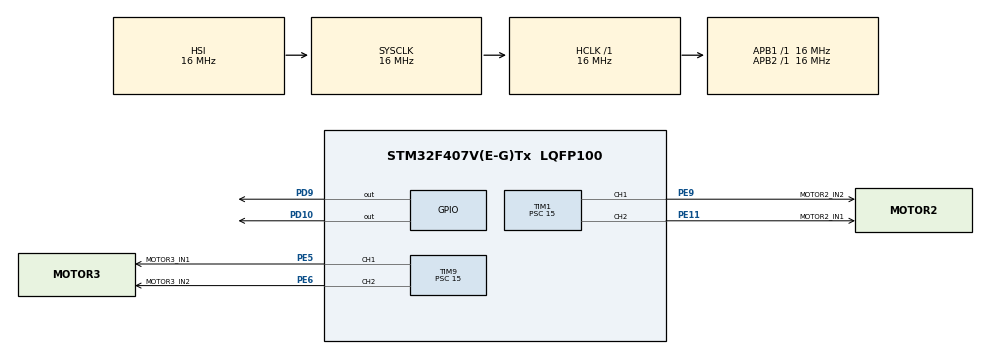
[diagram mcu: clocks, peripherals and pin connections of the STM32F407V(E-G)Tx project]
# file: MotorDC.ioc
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Mcu.Family=STM32F4
Mcu.Name=STM32F407V(E-G)Tx
Mcu.Package=LQFP100
NVIC.PriorityGroup=NVIC_PRIORITYGROUP_4
PD10.Signal=GPIO_Output
PD9.Signal=GPIO_Output
PE11.GPIO_Label=MOTOR2_IN1
PE11.Signal=S_TIM1_CH2
PE5.GPIO_Label=MOTOR3_IN1
PE5.Signal=S_TIM9_CH1
PE6.GPIO_Label=MOTOR3_IN2
PE6.Signal=S_TIM9_CH2
PE9.GPIO_Label=MOTOR2_IN2
PE9.Signal=S_TIM1_CH1
ProjectManager.HeapSize=0x200
ProjectManager.StackSize=0x400
ProjectManager.TargetToolchain=STM32CubeIDE
RCC.AHBFreq_Value=16000000
RCC.APB1Freq_Value=16000000
RCC.APB2Freq_Value=16000000
RCC.CortexFreq_Value=16000000
RCC.HSE_VALUE=25000000
RCC.HSI_VALUE=16000000
RCC.LSE_VALUE=32768
RCC.SYSCLKFreq_VALUE=16000000
RCC.VCOOutputFreq_Value=192000000
SH.S_TIM1_CH1.0=TIM1_CH1,PWM Generation1 CH1
SH.S_TIM1_CH2.0=TIM1_CH2,PWM Generation2 CH2
SH.S_TIM9_CH1.0=TIM9_CH1,PWM Generation1 CH1
SH.S_TIM9_CH2.0=TIM9_CH2,PWM Generation2 CH2
TIM1.Channel-PWM\ Generation1\ CH1=TIM_CHANNEL_1
TIM1.Channel-PWM\ Generation2\ CH2=TIM_CHANNEL_2
TIM1.Period=999
TIM1.Prescaler=15
TIM9.Channel-PWM\ Generation1\ CH1=TIM_CHANNEL_1
TIM9.Channel-PWM\ Generation2\ CH2=TIM_CHANNEL_2
TIM9.Period=999
TIM9.Prescaler=15
board=custom

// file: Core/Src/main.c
/* USER CODE BEGIN Header */
/**
  ******************************************************************************
  * @file           : main.c
  * @brief          : Main program body
  ******************************************************************************
  * @attention
  *
  * Copyright (c) 2026 STMicroelectronics.
  * All rights reserved.
  *
  * This software is licensed under terms that can be found in the LICENSE file
  * in the root directory of this software component.
  * If no LICENSE file comes with this software, it is provided AS-IS.
  *
  ******************************************************************************
  */
/* USER CODE END Header */
#include "main.h"

TIM_HandleTypeDef htim1;
TIM_HandleTypeDef htim9;

void SystemClock_Config(void);
static void MX_GPIO_Init(void);
static void MX_TIM1_Init(void);
static void MX_TIM9_Init(void);

int main(void)
{

  /* MCU Configuration--------------------------------------------------------*/

  /* Reset of all peripherals, Initializes the Flash interface and the Systick. */
  HAL_Init();

  /* Configure the system clock */
  SystemClock_Config();

  /* Initialize all configured peripherals */
  MX_GPIO_Init();
  MX_TIM1_Init();
  MX_TIM9_Init();
  /* USER CODE BEGIN 2 */
  // Encendemos los dos canales PWM del Motor 2

    // Encendemos los canales PWM del Motor 2 (M2)
  HAL_TIM_PWM_Start(&htim1, TIM_CHANNEL_1);
  HAL_TIM_PWM_Start(&htim1, TIM_CHANNEL_2);

    // Encendemos los canales PWM del Motor 3 (M3)
  HAL_TIM_PWM_Start(&htim9, TIM_CHANNEL_1); // PE5
  HAL_TIM_PWM_Start(&htim9, TIM_CHANNEL_2); // PE6

  /* USER CODE END 2 */

  /* Infinite loop */
  /* USER CODE BEGIN WHILE */
  /* USER CODE BEGIN WHILE */
    while (1)
    {
    /* USER CODE END WHILE */

    /* USER CODE BEGIN 3 */

    	/* USER CODE BEGIN 3 */

    	    // ==========================================
    	    // ESTADO 1: AVANZAR AMBOS AL 100% (Potencia Máxima)
    	    // ==========================================
    	    HAL_GPIO_WritePin(GPIOD, GPIO_PIN_9, GPIO_PIN_SET);   // Prende LED 1
    	    HAL_GPIO_WritePin(GPIOD, GPIO_PIN_10, GPIO_PIN_RESET);

    	    // Motor 2 (M2)
    	    __HAL_TIM_SET_COMPARE(&htim1, TIM_CHANNEL_1, 0);
    	    __HAL_TIM_SET_COMPARE(&htim1, TIM_CHANNEL_2, 1000);

    	    // Motor 3 (M3)
    	    __HAL_TIM_SET_COMPARE(&htim9, TIM_CHANNEL_1, 0); // IN1 activo
    	    __HAL_TIM_SET_COMPARE(&htim9, TIM_CHANNEL_2, 1000);    // IN2 apagado

    	    HAL_Delay(3000);

    	    // ==========================================
    	    // ESTADO 2: FRENAR AMBOS
    	    // ==========================================
    	    HAL_GPIO_WritePin(GPIOD, GPIO_PIN_9, GPIO_PIN_RESET);
    	    HAL_GPIO_WritePin(GPIOD, GPIO_PIN_10, GPIO_PIN_RESET);

    	    __HAL_TIM_SET_COMPARE(&htim1, TIM_CHANNEL_1, 0);
    	    __HAL_TIM_SET_COMPARE(&htim1, TIM_CHANNEL_2, 0);
    	    __HAL_TIM_SET_COMPARE(&htim9, TIM_CHANNEL_1, 0);
    	    __HAL_TIM_SET_COMPARE(&htim9, TIM_CHANNEL_2, 0);

    	    HAL_Delay(1000);

    	    // ==========================================
    	    // ESTADO 3: REVERSA AMBOS AL 100%
    	    // ==========================================
    	    HAL_GPIO_WritePin(GPIOD, GPIO_PIN_9, GPIO_PIN_RESET);
    	    HAL_GPIO_WritePin(GPIOD, GPIO_PIN_10, GPIO_PIN_SET);  // Prende LED 2

    	    // Motor 2 (M2)
    	    __HAL_TIM_SET_COMPARE(&htim1, TIM_CHANNEL_1, 1000);
    	    __HAL_TIM_SET_COMPARE(&htim1, TIM_CHANNEL_2, 0);

    	    // Motor 3 (M3)
    	    __HAL_TIM_SET_COMPARE(&htim9, TIM_CHANNEL_1, 1000);    // IN1 apagado
    	    __HAL_TIM_SET_COMPARE(&htim9, TIM_CHANNEL_2, 0); // IN2 activo

    	    HAL_Delay(3000);

    	    // ==========================================
    	    // ESTADO 4: FRENAR AMBOS
    	    // ==========================================
    	    HAL_GPIO_WritePin(GPIOD, GPIO_PIN_9, GPIO_PIN_RESET);
    	    HAL_GPIO_WritePin(GPIOD, GPIO_PIN_10, GPIO_PIN_RESET);

    	    __HAL_TIM_SET_COMPARE(&htim1, TIM_CHANNEL_1, 0);
    	    __HAL_TIM_SET_COMPARE(&htim1, TIM_CHANNEL_2, 0);
    	    __HAL_TIM_SET_COMPARE(&htim9, TIM_CHANNEL_1, 0);
    	    __HAL_TIM_SET_COMPARE(&htim9, TIM_CHANNEL_2, 0);

    	    HAL_Delay(1000);
    }
  /* USER CODE END 3 */.
}

void SystemClock_Config(void)
{
  RCC_OscInitTypeDef RCC_OscInitStruct = {0};
  RCC_ClkInitTypeDef RCC_ClkInitStruct = {0};

  /** Configure the main internal regulator output voltage
  */
  __HAL_RCC_PWR_CLK_ENABLE();
  __HAL_PWR_VOLTAGESCALING_CONFIG(PWR_REGULATOR_VOLTAGE_SCALE1);

  /** Initializes the RCC Oscillators according to the specified parameters
  * in the RCC_OscInitTypeDef structure.
  */
  RCC_OscInitStruct.OscillatorType = RCC_OSCILLATORTYPE_HSI;
  RCC_OscInitStruct.HSIState = RCC_HSI_ON;
  RCC_OscInitStruct.HSICalibrationValue = RCC_HSICALIBRATION_DEFAULT;
  RCC_OscInitStruct.PLL.PLLState = RCC_PLL_NONE;
  if (HAL_RCC_OscConfig(&RCC_OscInitStruct) != HAL_OK)
  {
    Error_Handler();
  }

  /** Initializes the CPU, AHB and APB buses clocks
  */
  RCC_ClkInitStruct.ClockType = RCC_CLOCKTYPE_HCLK|RCC_CLOCKTYPE_SYSCLK
                              |RCC_CLOCKTYPE_PCLK1|RCC_CLOCKTYPE_PCLK2;
  RCC_ClkInitStruct.SYSCLKSource = RCC_SYSCLKSOURCE_HSI;
  RCC_ClkInitStruct.AHBCLKDivider = RCC_SYSCLK_DIV1;
  RCC_ClkInitStruct.APB1CLKDivider = RCC_HCLK_DIV1;
  RCC_ClkInitStruct.APB2CLKDivider = RCC_HCLK_DIV1;

  if (HAL_RCC_ClockConfig(&RCC_ClkInitStruct, FLASH_LATENCY_0) != HAL_OK)
  {
    Error_Handler();
  }
}

static void MX_TIM1_Init(void)
{

  TIM_MasterConfigTypeDef sMasterConfig = {0};
  TIM_OC_InitTypeDef sConfigOC = {0};
  TIM_BreakDeadTimeConfigTypeDef sBreakDeadTimeConfig = {0};

  htim1.Instance = TIM1;
  htim1.Init.Prescaler = 15;
  htim1.Init.CounterMode = TIM_COUNTERMODE_UP;
  htim1.Init.Period = 999;
  htim1.Init.ClockDivision = TIM_CLOCKDIVISION_DIV1;
  htim1.Init.RepetitionCounter = 0;
  htim1.Init.AutoReloadPreload = TIM_AUTORELOAD_PRELOAD_DISABLE;
  if (HAL_TIM_PWM_Init(&htim1) != HAL_OK)
  {
    Error_Handler();
  }
  sMasterConfig.MasterOutputTrigger = TIM_TRGO_RESET;
  sMasterConfig.MasterSlaveMode = TIM_MASTERSLAVEMODE_DISABLE;
  if (HAL_TIMEx_MasterConfigSynchronization(&htim1, &sMasterConfig) != HAL_OK)
  {
    Error_Handler();
  }
  sConfigOC.OCMode = TIM_OCMODE_PWM1;
  sConfigOC.Pulse = 0;
  sConfigOC.OCPolarity = TIM_OCPOLARITY_HIGH;
  sConfigOC.OCNPolarity = TIM_OCNPOLARITY_HIGH;
  sConfigOC.OCFastMode = TIM_OCFAST_DISABLE;
  sConfigOC.OCIdleState = TIM_OCIDLESTATE_RESET;
  sConfigOC.OCNIdleState = TIM_OCNIDLESTATE_RESET;
  if (HAL_TIM_PWM_ConfigChannel(&htim1, &sConfigOC, TIM_CHANNEL_1) != HAL_OK)
  {
    Error_Handler();
  }
  if (HAL_TIM_PWM_ConfigChannel(&htim1, &sConfigOC, TIM_CHANNEL_2) != HAL_OK)
  {
    Error_Handler();
  }
  sBreakDeadTimeConfig.OffStateRunMode = TIM_OSSR_DISABLE;
  sBreakDeadTimeConfig.OffStateIDLEMode = TIM_OSSI_DISABLE;
  sBreakDeadTimeConfig.LockLevel = TIM_LOCKLEVEL_OFF;
  sBreakDeadTimeConfig.DeadTime = 0;
  sBreakDeadTimeConfig.BreakState = TIM_BREAK_DISABLE;
  sBreakDeadTimeConfig.BreakPolarity = TIM_BREAKPOLARITY_HIGH;
  sBreakDeadTimeConfig.AutomaticOutput = TIM_AUTOMATICOUTPUT_DISABLE;
  if (HAL_TIMEx_ConfigBreakDeadTime(&htim1, &sBreakDeadTimeConfig) != HAL_OK)
  {
    Error_Handler();
  }
  HAL_TIM_MspPostInit(&htim1);

}

static void MX_TIM9_Init(void)
{

  TIM_OC_InitTypeDef sConfigOC = {0};

  htim9.Instance = TIM9;
  htim9.Init.Prescaler = 15;
  htim9.Init.CounterMode = TIM_COUNTERMODE_UP;
  htim9.Init.Period = 999;
  htim9.Init.ClockDivision = TIM_CLOCKDIVISION_DIV1;
  htim9.Init.AutoReloadPreload = TIM_AUTORELOAD_PRELOAD_DISABLE;
  if (HAL_TIM_PWM_Init(&htim9) != HAL_OK)
  {
    Error_Handler();
  }
  sConfigOC.OCMode = TIM_OCMODE_PWM1;
  sConfigOC.Pulse = 0;
  sConfigOC.OCPolarity = TIM_OCPOLARITY_HIGH;
  sConfigOC.OCFastMode = TIM_OCFAST_DISABLE;
  if (HAL_TIM_PWM_ConfigChannel(&htim9, &sConfigOC, TIM_CHANNEL_1) != HAL_OK)
  {
    Error_Handler();
  }
  if (HAL_TIM_PWM_ConfigChannel(&htim9, &sConfigOC, TIM_CHANNEL_2) != HAL_OK)
  {
    Error_Handler();
  }
  HAL_TIM_MspPostInit(&htim9);

}

static void MX_GPIO_Init(void)
{
  GPIO_InitTypeDef GPIO_InitStruct = {0};

  /* GPIO Ports Clock Enable */
  __HAL_RCC_GPIOE_CLK_ENABLE();
  __HAL_RCC_GPIOD_CLK_ENABLE();

  /*Configure GPIO pin Output Level */
  HAL_GPIO_WritePin(GPIOD, GPIO_PIN_9|GPIO_PIN_10, GPIO_PIN_RESET);

  /*Configure GPIO pins : PD9 PD10 */
  GPIO_InitStruct.Pin = GPIO_PIN_9|GPIO_PIN_10;
  GPIO_InitStruct.Mode = GPIO_MODE_OUTPUT_PP;
  GPIO_InitStruct.Pull = GPIO_NOPULL;
  GPIO_InitStruct.Speed = GPIO_SPEED_FREQ_LOW;
  HAL_GPIO_Init(GPIOD, &GPIO_InitStruct);

}

void Error_Handler(void)
{
  __disable_irq();
  while (1)
  {
  }
}
